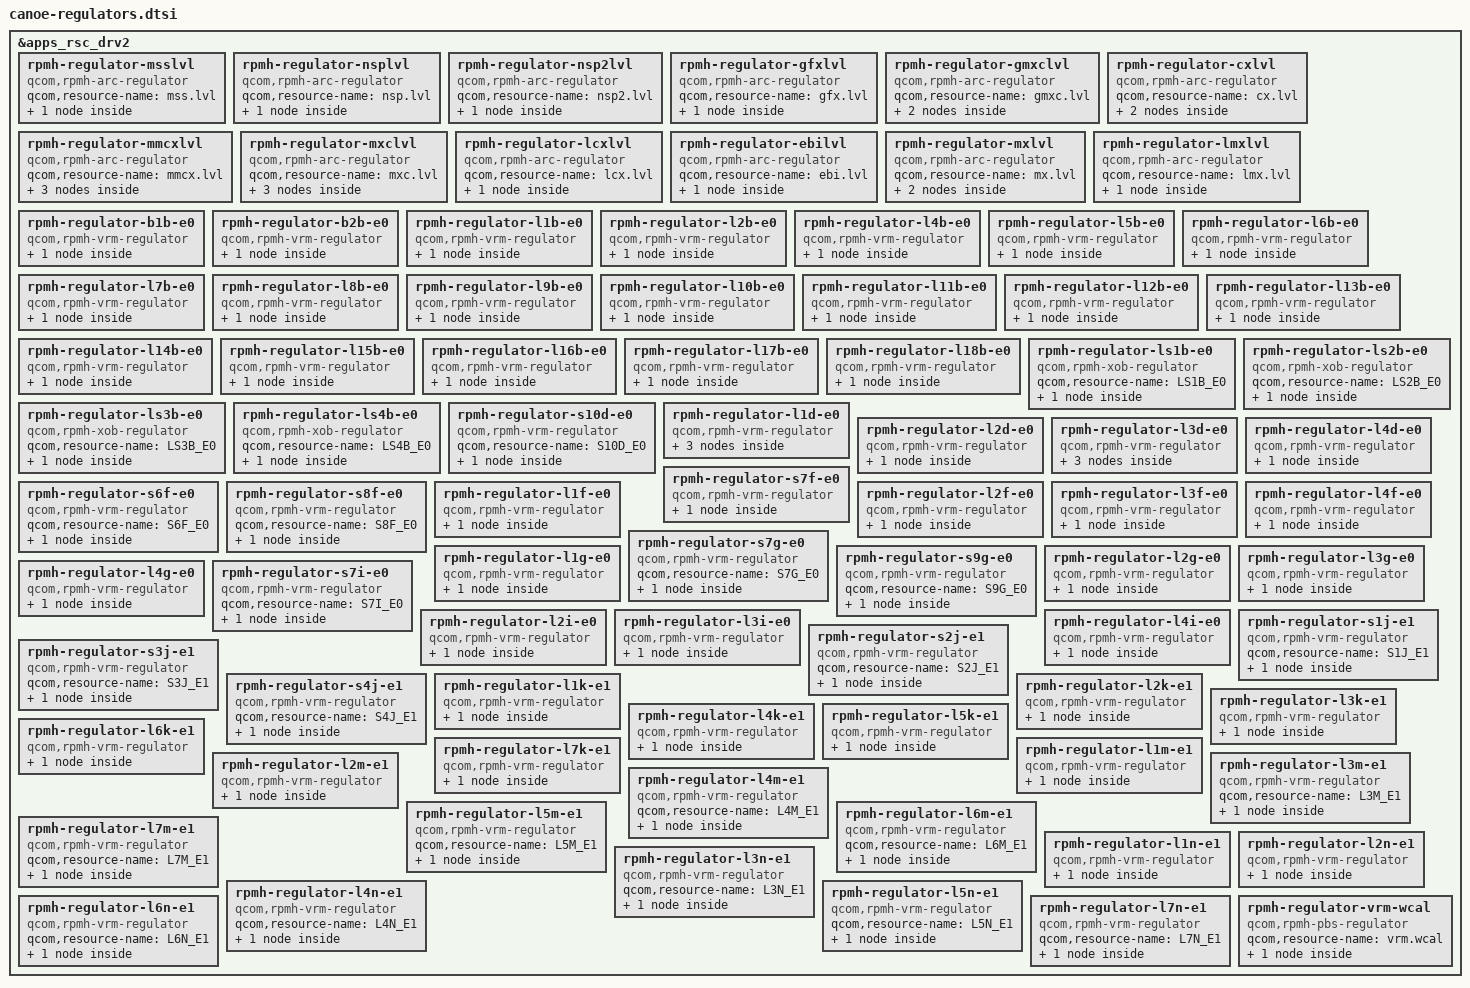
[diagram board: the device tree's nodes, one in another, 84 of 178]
// SPDX-License-Identifier: BSD-3-Clause
/*
 * Copyright (c) Qualcomm Technologies, Inc. and/or its subsidiaries.
 */

#include <dt-bindings/regulator/qcom,rpmh-regulator-levels.h>

&apps_rsc_drv2 {
	rpmh-regulator-msslvl {
		compatible = "qcom,rpmh-arc-regulator";
		qcom,resource-name = "mss.lvl";

		VDD_MODEM_LEVEL: S1D_LEVEL: S1D_E0_LEVEL:
		pmh0110_d_s1_level: regulator-pmh0110-d-s1-level {
			regulator-name = "pmh0110_d_s1_level";
			qcom,set = <RPMH_REGULATOR_SET_ALL>;
			regulator-min-microvolt =
				<RPMH_REGULATOR_LEVEL_RETENTION>;
			regulator-max-microvolt =
				<RPMH_REGULATOR_LEVEL_MAX>;
			qcom,init-voltage-level =
				<RPMH_REGULATOR_LEVEL_RETENTION>;
		};
	};

	rpmh-regulator-nsplvl {
		compatible = "qcom,rpmh-arc-regulator";
		qcom,resource-name = "nsp.lvl";

		/* VDD_NSP1: PMH0110_D S2-S3 */
		VDD_NSP1_LEVEL: S2D_LEVEL: S2D_E0_LEVEL:
		pmh0110_d_s2_level: regulator-pmh0110-d-s2-level {
			regulator-name = "pmh0110_d_s2_level";
			qcom,set = <RPMH_REGULATOR_SET_ALL>;
			regulator-min-microvolt =
				<RPMH_REGULATOR_LEVEL_RETENTION>;
			regulator-max-microvolt =
				<RPMH_REGULATOR_LEVEL_MAX>;
			qcom,init-voltage-level =
				<RPMH_REGULATOR_LEVEL_RETENTION>;
		};
	};

	rpmh-regulator-nsp2lvl {
		compatible = "qcom,rpmh-arc-regulator";
		qcom,resource-name = "nsp2.lvl";

		/* VDD_NSP2: PMH0110_D S4-S6 */
		VDD_NSP2_LEVEL: S4D_LEVEL: S4D_E0_LEVEL:
		pmh0110_d_s4_level: regulator-pmh0110-d-s4-level {
			regulator-name = "pmh0110_d_s4_level";
			qcom,set = <RPMH_REGULATOR_SET_ALL>;
			regulator-min-microvolt =
				<RPMH_REGULATOR_LEVEL_RETENTION>;
			regulator-max-microvolt =
				<RPMH_REGULATOR_LEVEL_MAX>;
			qcom,init-voltage-level =
				<RPMH_REGULATOR_LEVEL_RETENTION>;
		};
	};

	rpmh-regulator-gfxlvl {
		compatible = "qcom,rpmh-arc-regulator";
		qcom,resource-name = "gfx.lvl";

		/* VDD_GFX: PMH0110_F S1-S5 */
		VDD_GFX_LEVEL: S1F_LEVEL: S1F_E0_LEVEL:
		pmh0110_f_s1_level: regulator-pmh0110-f-s1-level {
			regulator-name = "pmh0110_f_s1_level";
			qcom,set = <RPMH_REGULATOR_SET_ALL>;
			regulator-min-microvolt =
				<RPMH_REGULATOR_LEVEL_RETENTION>;
			regulator-max-microvolt =
				<RPMH_REGULATOR_LEVEL_MAX>;
			qcom,init-voltage-level =
				<RPMH_REGULATOR_LEVEL_RETENTION>;
		};
	};

	rpmh-regulator-gmxclvl {
		compatible = "qcom,rpmh-arc-regulator";
		qcom,resource-name = "gmxc.lvl";

		VDD_GFX_MXC_LEVEL: S10F_LEVEL: S10F_E0_LEVEL:
		pmh0110_f_s10_level: regulator-pmh0110-f-s10-level {
			regulator-name = "pmh0110_f_s10_level";
			qcom,set = <RPMH_REGULATOR_SET_ALL>;
			regulator-min-microvolt =
				<RPMH_REGULATOR_LEVEL_RETENTION>;
			regulator-max-microvolt =
				<RPMH_REGULATOR_LEVEL_MAX>;
			qcom,init-voltage-level =
				<RPMH_REGULATOR_LEVEL_RETENTION>;
		};

		VDD_GFX_MXC_GFX_VOTER_LEVEL: VDD_GFX_GFX_MXC_VOTER_LEVEL:
		regulator-pmh0110-f-s10-gfx-voter-level {
			regulator-name = "pmh0110_f_s10_gfx_voter_level";
			qcom,set = <RPMH_REGULATOR_SET_ALL>;
			pmh0110_f_s10_gfx_voter_level-parent-supply =
				<&VDD_GFX_LEVEL>;
			regulator-min-microvolt =
				<RPMH_REGULATOR_LEVEL_MIN_SVS>;
			regulator-max-microvolt =
				<RPMH_REGULATOR_LEVEL_MAX>;
			qcom,init-voltage-level =
				<RPMH_REGULATOR_LEVEL_MIN_SVS>;
		};
	};

	rpmh-regulator-cxlvl {
		compatible = "qcom,rpmh-arc-regulator";
		qcom,resource-name = "cx.lvl";

		/* VDD_CX: PMH0110_G S5-S6 */
		VDD_CX_LEVEL: S5G_LEVEL: S5G_E0_LEVEL:
		pmh0110_g_s5_level: regulator-pmh0110-g-s5-level {
			regulator-name = "pmh0110_g_s5_level";
			qcom,set = <RPMH_REGULATOR_SET_ALL>;
			regulator-min-microvolt =
				<RPMH_REGULATOR_LEVEL_RETENTION>;
			regulator-max-microvolt =
				<RPMH_REGULATOR_LEVEL_MAX>;
			qcom,init-voltage-level =
				<RPMH_REGULATOR_LEVEL_TURBO>;
			proxy-supply = <&VDD_CX_LEVEL>;
			qcom,proxy-consumer-enable;
			qcom,proxy-consumer-voltage =
				<RPMH_REGULATOR_LEVEL_TURBO
				 RPMH_REGULATOR_LEVEL_MAX>;
		};

		VDD_CX_LEVEL_AO: S5G_LEVEL_AO: S5G_E0_LEVEL_AO:
		pmh0110_g_s5_level_ao: regulator-pmh0110-g-s5-level-ao {
			regulator-name = "pmh0110_g_s5_level_ao";
			qcom,set = <RPMH_REGULATOR_SET_ACTIVE>;
			regulator-min-microvolt =
				<RPMH_REGULATOR_LEVEL_RETENTION>;
			regulator-max-microvolt =
				<RPMH_REGULATOR_LEVEL_MAX>;
			qcom,init-voltage-level =
				<RPMH_REGULATOR_LEVEL_RETENTION>;
		};
	};

	rpmh-regulator-mmcxlvl {
		compatible = "qcom,rpmh-arc-regulator";
		qcom,resource-name = "mmcx.lvl";

		/* VDD_MMCX: PMH0110_D S7-S9 */
		VDD_MMCX_LEVEL: VDD_MM_LEVEL: S7D_LEVEL: S7D_E0_LEVEL:
		pmh0110_d_s7_level: regulator-pmh0110-d-s7-level {
			regulator-name = "pmh0110_d_s7_level";
			qcom,set = <RPMH_REGULATOR_SET_ALL>;
			regulator-min-microvolt =
				<RPMH_REGULATOR_LEVEL_LOW_SVS_D1>;
			regulator-max-microvolt =
				<RPMH_REGULATOR_LEVEL_MAX>;
			qcom,init-voltage-level =
				<RPMH_REGULATOR_LEVEL_TURBO>;
			proxy-supply = <&VDD_MMCX_LEVEL>;
			qcom,proxy-consumer-enable;
			qcom,proxy-consumer-voltage =
				<RPMH_REGULATOR_LEVEL_TURBO
				 RPMH_REGULATOR_LEVEL_MAX>;
		};

		VDD_MMCX_LEVEL_AO: VDD_MM_LEVEL_AO: S7D_LEVEL_AO: S7D_E0_LEVEL_AO:
		pmh0110_d_s7_level_ao: regulator-pmh0110-d-s7-level-ao {
			regulator-name = "pmh0110_d_s7_level_ao";
			qcom,set = <RPMH_REGULATOR_SET_ACTIVE>;
			regulator-min-microvolt =
				<RPMH_REGULATOR_LEVEL_LOW_SVS_D1>;
			regulator-max-microvolt =
				<RPMH_REGULATOR_LEVEL_MAX>;
			qcom,init-voltage-level =
				<RPMH_REGULATOR_LEVEL_LOW_SVS_D1>;
		};

		regulator-pmh0110-d-s7-level-so {
			regulator-name = "pmh0110_d_s7_level_so";
			qcom,set = <RPMH_REGULATOR_SET_SLEEP>;
			regulator-min-microvolt =
				<RPMH_REGULATOR_LEVEL_LOW_SVS_D1>;
			regulator-max-microvolt =
				<RPMH_REGULATOR_LEVEL_MAX>;
			qcom,init-voltage-level =
				<RPMH_REGULATOR_LEVEL_LOW_SVS_D1>;
		};
	};

	rpmh-regulator-mxclvl {
		compatible = "qcom,rpmh-arc-regulator";
		qcom,resource-name = "mxc.lvl";

		VDD_MXC_LEVEL: S9F_LEVEL: S9F_E0_LEVEL:
		pmh0110_f_s9_level: regulator-pmh0110-f-s9-level {
			regulator-name = "pmh0110_f_s9_level";
			qcom,set = <RPMH_REGULATOR_SET_ALL>;
			regulator-min-microvolt =
				<RPMH_REGULATOR_LEVEL_RETENTION>;
			regulator-max-microvolt =
				<RPMH_REGULATOR_LEVEL_MAX>;
			qcom,init-voltage-level =
				<RPMH_REGULATOR_LEVEL_TURBO>;
			proxy-supply = <&VDD_MXC_LEVEL>;
			qcom,proxy-consumer-enable;
			qcom,proxy-consumer-voltage =
				<RPMH_REGULATOR_LEVEL_TURBO
				 RPMH_REGULATOR_LEVEL_MAX>;
		};

		VDD_MXC_LEVEL_AO: S9F_LEVEL_AO: S9F_E0_LEVEL_AO:
		pmh0110_f_s9_level_ao: regulator-pmh0110-f-s9-level-ao {
			regulator-name = "pmh0110_f_s9_level_ao";
			qcom,set = <RPMH_REGULATOR_SET_ACTIVE>;
			regulator-min-microvolt =
				<RPMH_REGULATOR_LEVEL_RETENTION>;
			regulator-max-microvolt =
				<RPMH_REGULATOR_LEVEL_MAX>;
			qcom,init-voltage-level =
				<RPMH_REGULATOR_LEVEL_RETENTION>;
		};

		VDD_MXC_MMCX_VOTER_LEVEL: VDD_MXC_MM_VOTER_LEVEL:
		VDD_MM_MXC_VOTER_LEVEL: regulator-pmh0110-f-s9-mmcx-voter-level {
			regulator-name = "pmh0110_f_s9_mmcx_voter_level";
			qcom,set = <RPMH_REGULATOR_SET_ALL>;
			pmh0110_f_s9_mmcx_voter_level-parent-supply =
				<&VDD_MMCX_LEVEL>;
			regulator-min-microvolt =
				<RPMH_REGULATOR_LEVEL_MIN_SVS>;
			regulator-max-microvolt =
				<RPMH_REGULATOR_LEVEL_MAX>;
			qcom,init-voltage-level =
				<RPMH_REGULATOR_LEVEL_MIN_SVS>;
		};
	};

	rpmh-regulator-lcxlvl {
		compatible = "qcom,rpmh-arc-regulator";
		qcom,resource-name = "lcx.lvl";

		VDD_LPI_CX_LEVEL: S8G_LEVEL: S8G_E0_LEVEL:
		pmh0110_g_s8_level: regulator-pmh0110-g-s8-level {
			regulator-name = "pmh0110_g_s8_level";
			qcom,set = <RPMH_REGULATOR_SET_ALL>;
			regulator-min-microvolt =
				<RPMH_REGULATOR_LEVEL_RETENTION>;
			regulator-max-microvolt =
				<RPMH_REGULATOR_LEVEL_MAX>;
			qcom,init-voltage-level =
				<RPMH_REGULATOR_LEVEL_RETENTION>;
		};
	};

	rpmh-regulator-ebilvl {
		compatible = "qcom,rpmh-arc-regulator";
		qcom,resource-name = "ebi.lvl";

		VDD_EBI_LEVEL: S1I_LEVEL: S1I_E0_LEVEL:
		pmh0110_i_s1_level: regulator-pmh0110-i-s1-level {
			regulator-name = "pmh0110_i_s1_level";
			qcom,set = <RPMH_REGULATOR_SET_ALL>;
			regulator-min-microvolt =
				<RPMH_REGULATOR_LEVEL_RETENTION>;
			regulator-max-microvolt =
				<RPMH_REGULATOR_LEVEL_MAX>;
			qcom,init-voltage-level =
				<RPMH_REGULATOR_LEVEL_RETENTION>;
		};
	};

	rpmh-regulator-mxlvl {
		compatible = "qcom,rpmh-arc-regulator";
		qcom,resource-name = "mx.lvl";

		VDD_MXA_LEVEL: VDD_MX_LEVEL: S10I_LEVEL: S10I_E0_LEVEL:
		pmh0110_i_s10_level: regulator-pmh0110-i-s10-level {
			regulator-name = "pmh0110_i_s10_level";
			qcom,set = <RPMH_REGULATOR_SET_ALL>;
			regulator-min-microvolt =
				<RPMH_REGULATOR_LEVEL_RETENTION>;
			regulator-max-microvolt =
				<RPMH_REGULATOR_LEVEL_MAX>;
			qcom,init-voltage-level =
				<RPMH_REGULATOR_LEVEL_TURBO>;
			proxy-supply = <&VDD_MXA_LEVEL>;
			qcom,proxy-consumer-enable;
			qcom,proxy-consumer-voltage =
				<RPMH_REGULATOR_LEVEL_TURBO
				 RPMH_REGULATOR_LEVEL_MAX>;
		};

		VDD_MXA_LEVEL_AO: VDD_MX_LEVEL_AO: S10I_LEVEL_AO: S10I_E0_LEVEL_AO:
		pmh0110_i_s10_level_ao: regulator-pmh0110-i-s10-level-ao {
			regulator-name = "pmh0110_i_s10_level_ao";
			qcom,set = <RPMH_REGULATOR_SET_ACTIVE>;
			regulator-min-microvolt =
				<RPMH_REGULATOR_LEVEL_RETENTION>;
			regulator-max-microvolt =
				<RPMH_REGULATOR_LEVEL_MAX>;
			qcom,init-voltage-level =
				<RPMH_REGULATOR_LEVEL_RETENTION>;
		};
	};

	rpmh-regulator-lmxlvl {
		compatible = "qcom,rpmh-arc-regulator";
		qcom,resource-name = "lmx.lvl";

		VDD_LPI_MX_LEVEL: L1I_LEVEL: L1I_E0_LEVEL:
		pmh0110_i_l1_level: regulator-pmh0110-i-l1-level {
			regulator-name = "pmh0110_i_l1_level";
			qcom,set = <RPMH_REGULATOR_SET_ALL>;
			regulator-min-microvolt =
				<RPMH_REGULATOR_LEVEL_RETENTION>;
			regulator-max-microvolt =
				<RPMH_REGULATOR_LEVEL_MAX>;
			qcom,init-voltage-level =
				<RPMH_REGULATOR_LEVEL_RETENTION>;
		};
	};

	rpmh-regulator-b1b-e0 {
		compatible = "qcom,rpmh-vrm-regulator";
		qcom,resource-name = "B1B_E0";
		qcom,regulator-type = "pmic5-bob";
		qcom,supported-modes =
			<RPMH_REGULATOR_MODE_PASS
			RPMH_REGULATOR_MODE_AUTO
			RPMH_REGULATOR_MODE_HPM>;
		qcom,mode-threshold-currents = <0 1000000 2000000>;

		BOB1: BOB1_E0: pmh0101_bob1: regulator-pmh0101-bob1 {
			regulator-name = "pmh0101_bob1";
			qcom,set = <RPMH_REGULATOR_SET_ALL>;
			regulator-min-microvolt = <3008000>;
			regulator-max-microvolt = <4000000>;
			qcom,init-voltage = <3296000>;
			qcom,init-mode = <RPMH_REGULATOR_MODE_PASS>;
		};
	};

	rpmh-regulator-b2b-e0 {
		compatible = "qcom,rpmh-vrm-regulator";
		qcom,resource-name = "B2B_E0";
		qcom,regulator-type = "pmic5-bob";
		qcom,supported-modes =
			<RPMH_REGULATOR_MODE_PASS
			RPMH_REGULATOR_MODE_AUTO
			RPMH_REGULATOR_MODE_HPM>;
		qcom,mode-threshold-currents = <0 1000000 2000000>;

		BOB2: BOB2_E0: pmh0101_bob2: regulator-pmh0101-bob2 {
			regulator-name = "pmh0101_bob2";
			qcom,set = <RPMH_REGULATOR_SET_ALL>;
			regulator-min-microvolt = <2704000>;
			regulator-max-microvolt = <3552000>;
			qcom,init-voltage = <2720000>;
			qcom,init-mode = <RPMH_REGULATOR_MODE_PASS>;
		};
	};

	rpmh-regulator-l1b-e0 {
		compatible = "qcom,rpmh-vrm-regulator";
		qcom,resource-name = "L1B_E0";
		qcom,regulator-type = "pmic7-ldo";
		qcom,supported-modes = <RPMH_REGULATOR_MODE_LPM
					RPMH_REGULATOR_MODE_AUTO>;
		qcom,mode-threshold-currents = <0 30000>;

		L1B: L1B_E0: pmh0101_l1: regulator-pmh0101-l1 {
			regulator-name = "pmh0101_l1";
			qcom,set = <RPMH_REGULATOR_SET_ALL>;
			regulator-min-microvolt = <1800000>;
			regulator-max-microvolt = <1800000>;
			qcom,init-voltage = <1800000>;
			qcom,init-mode = <RPMH_REGULATOR_MODE_AUTO>;
		};
	};

	rpmh-regulator-l2b-e0 {
		compatible = "qcom,rpmh-vrm-regulator";
		qcom,resource-name = "L2B_E0";
		qcom,regulator-type = "pmic7-ldo";
		qcom,supported-modes = <RPMH_REGULATOR_MODE_LPM
					RPMH_REGULATOR_MODE_AUTO>;
		qcom,mode-threshold-currents = <0 20000>;

		L2B: L2B_E0: pmh0101_l2: regulator-pmh0101-l2 {
			regulator-name = "pmh0101_l2";
			qcom,set = <RPMH_REGULATOR_SET_ALL>;
			regulator-min-microvolt = <3008000>;
			regulator-max-microvolt = <3048000>;
			qcom,init-voltage = <3008000>;
			qcom,init-mode = <RPMH_REGULATOR_MODE_AUTO>;
		};
	};

	rpmh-regulator-l4b-e0 {
		compatible = "qcom,rpmh-vrm-regulator";
		qcom,resource-name = "L4B_E0";
		qcom,regulator-type = "pmic7-ldo";
		qcom,supported-modes = <RPMH_REGULATOR_MODE_LPM
					RPMH_REGULATOR_MODE_AUTO>;
		qcom,mode-threshold-currents = <0 30000>;

		L4B: L4B_E0: pmh0101_l4: regulator-pmh0101-l4 {
			regulator-name = "pmh0101_l4";
			qcom,set = <RPMH_REGULATOR_SET_ALL>;
			regulator-min-microvolt = <1800000>;
			regulator-max-microvolt = <1800000>;
			qcom,init-voltage = <1800000>;
			qcom,init-mode = <RPMH_REGULATOR_MODE_AUTO>;
		};
	};

	rpmh-regulator-l5b-e0 {
		compatible = "qcom,rpmh-vrm-regulator";
		qcom,resource-name = "L5B_E0";
		qcom,regulator-type = "pmic7-ldo";
		qcom,supported-modes = <RPMH_REGULATOR_MODE_LPM
					RPMH_REGULATOR_MODE_AUTO>;
		qcom,mode-threshold-currents = <0 10000>;

		L5B: L5B_E0: pmh0101_l5: regulator-pmh0101-l5 {
			regulator-name = "pmh0101_l5";
			qcom,set = <RPMH_REGULATOR_SET_ALL>;
			regulator-min-microvolt = <3100000>;
			regulator-max-microvolt = <3148000>;
			qcom,init-voltage = <3104000>;
			qcom,init-mode = <RPMH_REGULATOR_MODE_AUTO>;
		};
	};

	rpmh-regulator-l6b-e0 {
		compatible = "qcom,rpmh-vrm-regulator";
		qcom,resource-name = "L6B_E0";
		qcom,regulator-type = "pmic7-ldo";
		qcom,supported-modes = <RPMH_REGULATOR_MODE_LPM
					RPMH_REGULATOR_MODE_AUTO>;
		qcom,mode-threshold-currents = <0 20000>;

		L6B: L6B_E0: pmh0101_l6: regulator-pmh0101-l6 {
			regulator-name = "pmh0101_l6";
			qcom,set = <RPMH_REGULATOR_SET_ALL>;
			regulator-min-microvolt = <1800000>;
			regulator-max-microvolt = <3008000>;
			qcom,init-voltage = <1800000>;
			qcom,init-mode = <RPMH_REGULATOR_MODE_AUTO>;
		};
	};

	rpmh-regulator-l7b-e0 {
		compatible = "qcom,rpmh-vrm-regulator";
		qcom,resource-name = "L7B_E0";
		qcom,regulator-type = "pmic7-ldo";
		qcom,supported-modes = <RPMH_REGULATOR_MODE_LPM
					RPMH_REGULATOR_MODE_AUTO>;
		qcom,mode-threshold-currents = <0 20000>;

		L7B: L7B_E0: pmh0101_l7: regulator-pmh0101-l7 {
			regulator-name = "pmh0101_l7";
			qcom,set = <RPMH_REGULATOR_SET_ALL>;
			regulator-min-microvolt = <1800000>;
			regulator-max-microvolt = <3008000>;
			qcom,init-voltage = <1800000>;
			qcom,init-mode = <RPMH_REGULATOR_MODE_AUTO>;
		};
	};

	rpmh-regulator-l8b-e0 {
		compatible = "qcom,rpmh-vrm-regulator";
		qcom,resource-name = "L8B_E0";
		qcom,regulator-type = "pmic7-ldo";
		qcom,supported-modes = <RPMH_REGULATOR_MODE_LPM
					RPMH_REGULATOR_MODE_AUTO>;
		qcom,mode-threshold-currents = <0 10000>;

		L8B: L8B_E0: pmh0101_l8: regulator-pmh0101-l8 {
			regulator-name = "pmh0101_l8";
			qcom,set = <RPMH_REGULATOR_SET_ALL>;
			regulator-min-microvolt = <1800000>;
			regulator-max-microvolt = <3008000>;
			qcom,init-voltage = <1800000>;
			qcom,init-mode = <RPMH_REGULATOR_MODE_AUTO>;
		};
	};

	rpmh-regulator-l9b-e0 {
		compatible = "qcom,rpmh-vrm-regulator";
		qcom,resource-name = "L9B_E0";
		qcom,regulator-type = "pmic5-ldo";
		qcom,supported-modes = <RPMH_REGULATOR_MODE_LPM
					RPMH_REGULATOR_MODE_HPM>;
		qcom,mode-threshold-currents = <0 80000>;

		L9B: L9B_E0: pmh0101_l9: regulator-pmh0101-l9 {
			regulator-name = "pmh0101_l9";
			qcom,set = <RPMH_REGULATOR_SET_ALL>;
			regulator-min-microvolt = <2960000>;
			regulator-max-microvolt = <3300000>;
			qcom,init-voltage = <2960000>;
			qcom,init-mode = <RPMH_REGULATOR_MODE_HPM>;
		};
	};

	rpmh-regulator-l10b-e0 {
		compatible = "qcom,rpmh-vrm-regulator";
		qcom,resource-name = "L10B_E0";
		qcom,regulator-type = "pmic7-ldo";
		qcom,supported-modes = <RPMH_REGULATOR_MODE_LPM
					RPMH_REGULATOR_MODE_AUTO>;
		qcom,mode-threshold-currents = <0 30000>;
		proxy-supply = <&L10B>;

		L10B: L10B_E0: pmh0101_l10: regulator-pmh0101-l10 {
			regulator-name = "pmh0101_l10";
			qcom,set = <RPMH_REGULATOR_SET_ALL>;
			regulator-min-microvolt = <1800000>;
			regulator-max-microvolt = <1800000>;
			qcom,init-voltage = <1800000>;
			qcom,init-mode = <RPMH_REGULATOR_MODE_AUTO>;
			qcom,proxy-consumer-enable;
		};
	};

	rpmh-regulator-l11b-e0 {
		compatible = "qcom,rpmh-vrm-regulator";
		qcom,resource-name = "L11B_E0";
		qcom,regulator-type = "pmic7-ldo";
		qcom,supported-modes = <RPMH_REGULATOR_MODE_LPM
					RPMH_REGULATOR_MODE_AUTO>;
		qcom,mode-threshold-currents = <0 30000>;
		proxy-supply = <&L11B>;

		L11B: L11B_E0: pmh0101_l11: regulator-pmh0101-l11 {
			regulator-name = "pmh0101_l11";
			qcom,set = <RPMH_REGULATOR_SET_ALL>;
			regulator-min-microvolt = <1000000>;
			regulator-max-microvolt = <1292000>;
			qcom,init-voltage = <1064000>;
			qcom,init-mode = <RPMH_REGULATOR_MODE_AUTO>;
			qcom,proxy-consumer-enable;
		};
	};

	rpmh-regulator-l12b-e0 {
		compatible = "qcom,rpmh-vrm-regulator";
		qcom,resource-name = "L12B_E0";
		qcom,regulator-type = "pmic7-ldo";
		qcom,supported-modes = <RPMH_REGULATOR_MODE_LPM
					RPMH_REGULATOR_MODE_AUTO>;
		qcom,mode-threshold-currents = <0 30000>;
		proxy-supply = <&L12B>;

		L12B: L12B_E0: pmh0101_l12: regulator-pmh0101-l12 {
			regulator-name = "pmh0101_l12";
			qcom,set = <RPMH_REGULATOR_SET_ALL>;
			regulator-min-microvolt = <1200000>;
			regulator-max-microvolt = <1800000>;
			qcom,init-voltage = <1800000>;
			qcom,init-mode = <RPMH_REGULATOR_MODE_AUTO>;
			qcom,proxy-consumer-enable;
		};
	};

	rpmh-regulator-l13b-e0 {
		compatible = "qcom,rpmh-vrm-regulator";
		qcom,resource-name = "L13B_E0";
		qcom,regulator-type = "pmic7-ldo";
		qcom,supported-modes = <RPMH_REGULATOR_MODE_LPM
					RPMH_REGULATOR_MODE_AUTO>;
		qcom,mode-threshold-currents = <0 10000>;
		proxy-supply = <&L13B>;

		L13B: L13B_E0: pmh0101_l13: regulator-pmh0101-l13 {
			regulator-name = "pmh0101_l13";
			qcom,set = <RPMH_REGULATOR_SET_ALL>;
			regulator-min-microvolt = <3000000>;
			regulator-max-microvolt = <3000000>;
			qcom,init-voltage = <3000000>;
			qcom,init-mode = <RPMH_REGULATOR_MODE_AUTO>;
			qcom,proxy-consumer-enable;
		};
	};

	rpmh-regulator-l14b-e0 {
		compatible = "qcom,rpmh-vrm-regulator";
		qcom,resource-name = "L14B_E0";
		qcom,regulator-type = "pmic7-ldo";
		qcom,supported-modes = <RPMH_REGULATOR_MODE_LPM
					RPMH_REGULATOR_MODE_AUTO>;
		qcom,mode-threshold-currents = <0 10000>;

		L14B: L14B_E0: pmh0101_l14: regulator-pmh0101-l14 {
			regulator-name = "pmh0101_l14";
			qcom,set = <RPMH_REGULATOR_SET_ALL>;
			regulator-min-microvolt = <3200000>;
			regulator-max-microvolt = <3200000>;
			qcom,init-voltage = <3200000>;
			qcom,init-mode = <RPMH_REGULATOR_MODE_AUTO>;
		};
	};

	rpmh-regulator-l15b-e0 {
		compatible = "qcom,rpmh-vrm-regulator";
		qcom,resource-name = "L15B_E0";
		qcom,regulator-type = "pmic7-ldo";
		qcom,supported-modes = <RPMH_REGULATOR_MODE_LPM
					RPMH_REGULATOR_MODE_AUTO>;
		qcom,mode-threshold-currents = <0 30000>;

		L15B: L15B_E0: pmh0101_l15: regulator-pmh0101-l15 {
			regulator-name = "pmh0101_l15";
			qcom,set = <RPMH_REGULATOR_SET_ALL>;
			regulator-min-microvolt = <1800000>;
			regulator-max-microvolt = <1800000>;
			qcom,init-voltage = <1800000>;
			qcom,init-mode = <RPMH_REGULATOR_MODE_AUTO>;
		};
	};

	rpmh-regulator-l16b-e0 {
		compatible = "qcom,rpmh-vrm-regulator";
		qcom,resource-name = "L16B_E0";
		qcom,regulator-type = "pmic7-ldo";
		qcom,supported-modes = <RPMH_REGULATOR_MODE_LPM
					RPMH_REGULATOR_MODE_HPM>;
		qcom,mode-threshold-currents = <0 10000>;

		L16B: L16B_E0: pmh0101_l16: regulator-pmh0101-l16 {
			regulator-name = "pmh0101_l16";
			qcom,set = <RPMH_REGULATOR_SET_ALL>;
			regulator-min-microvolt = <1504000>;
			regulator-max-microvolt = <3300000>;
			qcom,init-voltage = <3300000>;
			qcom,init-mode = <RPMH_REGULATOR_MODE_HPM>;
		};
	};

	rpmh-regulator-l17b-e0 {
		compatible = "qcom,rpmh-vrm-regulator";
		qcom,resource-name = "L17B_E0";
		qcom,regulator-type = "pmic5-ldo";
		qcom,supported-modes = <RPMH_REGULATOR_MODE_LPM
					RPMH_REGULATOR_MODE_HPM>;
		qcom,mode-threshold-currents = <0 80000>;

		L17B: L17B_E0: pmh0101_l17: regulator-pmh0101-l17 {
			regulator-name = "pmh0101_l17";
			qcom,set = <RPMH_REGULATOR_SET_ALL>;
			regulator-min-microvolt = <2504000>;
			regulator-max-microvolt = <2504000>;
			qcom,init-voltage = <2504000>;
			qcom,init-mode = <RPMH_REGULATOR_MODE_HPM>;
		};
	};

	rpmh-regulator-l18b-e0 {
		compatible = "qcom,rpmh-vrm-regulator";
		qcom,resource-name = "L18B_E0";
		qcom,regulator-type = "pmic7-ldo";
		qcom,supported-modes = <RPMH_REGULATOR_MODE_LPM
					RPMH_REGULATOR_MODE_AUTO>;
		qcom,mode-threshold-currents = <0 30000>;

		L18B: L18B_E0: pmh0101_l18: regulator-pmh0101-l18 {
			regulator-name = "pmh0101_l18";
			qcom,set = <RPMH_REGULATOR_SET_ALL>;
			regulator-min-microvolt = <1200000>;
			regulator-max-microvolt = <1200000>;
			qcom,init-voltage = <1200000>;
			qcom,init-mode = <RPMH_REGULATOR_MODE_AUTO>;
		};
	};

	rpmh-regulator-ls1b-e0 {
		compatible = "qcom,rpmh-xob-regulator";
		qcom,resource-name = "LS1B_E0";

		/* PMH0101 GPIO 11 and 12 bi-directional level-shifter */
		LS1B: LS1B_E0: pmh0101_ls1: regulator-pmh0101-ls1 {
			regulator-name = "pmh0101_ls1";
			qcom,set = <RPMH_REGULATOR_SET_ALL>;
		};
	};

	rpmh-regulator-ls2b-e0 {
		compatible = "qcom,rpmh-xob-regulator";
		qcom,resource-name = "LS2B_E0";

		/* PMH0101 GPIO 13 and 14 bi-directional level-shifter */
		LS2B: LS2B_E0: pmh0101_ls2: regulator-pmh0101-ls2 {
			regulator-name = "pmh0101_ls2";
			qcom,set = <RPMH_REGULATOR_SET_ALL>;
		};
	};

	rpmh-regulator-ls3b-e0 {
		compatible = "qcom,rpmh-xob-regulator";
		qcom,resource-name = "LS3B_E0";

		/* PMH0101 GPIO 15 and 16 bi-directional level-shifter */
		LS3B: LS3B_E0: pmh0101_ls3: regulator-pmh0101-ls3 {
			regulator-name = "pmh0101_ls3";
			qcom,set = <RPMH_REGULATOR_SET_ALL>;
		};
	};

	rpmh-regulator-ls4b-e0 {
		compatible = "qcom,rpmh-xob-regulator";
		qcom,resource-name = "LS4B_E0";

		/* PMH0101 GPIO 17 and 18 bi-directional level-shifter */
		LS4B: LS4B_E0: pmh0101_ls4: regulator-pmh0101-ls4 {
			regulator-name = "pmh0101_ls4";
			qcom,set = <RPMH_REGULATOR_SET_ALL>;
		};
	};

	rpmh-regulator-s10d-e0 {
		compatible = "qcom,rpmh-vrm-regulator";
		qcom,resource-name = "S10D_E0";

		S10D: S10D_E0: pmh0110_d_s10: regulator-pmh0110-d-s10 {
			regulator-name = "pmh0110_d_s10";
			qcom,set = <RPMH_REGULATOR_SET_ALL>;
			regulator-min-microvolt = <1000000>;
			regulator-max-microvolt = <1100000>;
			qcom,init-voltage = <1052000>;
		};
	};

	rpmh-regulator-l1d-e0 {
		compatible = "qcom,rpmh-vrm-regulator";
		qcom,resource-name = "L1D_E0";
		qcom,regulator-type = "pmic7-ldo";
		qcom,supported-modes = <RPMH_REGULATOR_MODE_LPM
					RPMH_REGULATOR_MODE_AUTO>;
		qcom,mode-threshold-currents = <0 30000>;
		qcom,send-defaults;
		proxy-supply = <&L1D>;

		L1D: L1D_E0: pmh0110_d_l1: regulator-pmh0110-d-l1 {
			regulator-name = "pmh0110_d_l1";
			qcom,set = <RPMH_REGULATOR_SET_ALL>;
			regulator-min-microvolt = <1200000>;
			regulator-max-microvolt = <1256000>;
			qcom,init-voltage = <1200000>;
			qcom,init-mode = <RPMH_REGULATOR_MODE_AUTO>;
			qcom,proxy-consumer-enable;
		};

		L1D_AO: L1D_E0_AO: pmh0110_d_l1_ao: regulator-pmh0110-d-l1-ao {
			regulator-name = "pmh0110_d_l1_ao";
			qcom,set = <RPMH_REGULATOR_SET_ACTIVE>;
			regulator-min-microvolt = <1200000>;
			regulator-max-microvolt = <1256000>;
			qcom,init-voltage = <1200000>;
			qcom,init-mode = <RPMH_REGULATOR_MODE_AUTO>;
			regulator-always-on;
		};

		regulator-pmh0110-d-l1-so {
			regulator-name = "pmh0110_d_l1_so";
			qcom,set = <RPMH_REGULATOR_SET_SLEEP>;
			regulator-min-microvolt = <1200000>;
			regulator-max-microvolt = <1256000>;
			qcom,init-voltage = <1200000>;
			qcom,init-mode = <RPMH_REGULATOR_MODE_LPM>;
			qcom,init-enable = <0>;
		};
	};

	rpmh-regulator-l2d-e0 {
		compatible = "qcom,rpmh-vrm-regulator";
		qcom,resource-name = "L2D_E0";
		qcom,regulator-type = "pmic7-ldo";
		qcom,supported-modes = <RPMH_REGULATOR_MODE_LPM
					RPMH_REGULATOR_MODE_AUTO>;
		qcom,mode-threshold-currents = <0 30000>;

		L2D: L2D_E0: pmh0110_d_l2: regulator-pmh0110-d-l2 {
			regulator-name = "pmh0110_d_l2";
			qcom,set = <RPMH_REGULATOR_SET_ALL>;
			regulator-min-microvolt = <912000>;
			regulator-max-microvolt = <958000>;
			qcom,init-voltage = <912000>;
			qcom,init-mode = <RPMH_REGULATOR_MODE_AUTO>;
		};
	};

	rpmh-regulator-l3d-e0 {
		compatible = "qcom,rpmh-vrm-regulator";
		qcom,resource-name = "L3D_E0";
		qcom,regulator-type = "pmic7-ldo";
		qcom,supported-modes = <RPMH_REGULATOR_MODE_LPM
					RPMH_REGULATOR_MODE_AUTO>;
		qcom,mode-threshold-currents = <0 30000>;
		qcom,send-defaults;
		proxy-supply = <&L3D>;

		L3D: L3D_E0: pmh0110_d_l3: regulator-pmh0110-d-l3 {
			regulator-name = "pmh0110_d_l3";
			qcom,set = <RPMH_REGULATOR_SET_ALL>;
			regulator-min-microvolt = <880000>;
			regulator-max-microvolt = <880000>;
			qcom,init-voltage = <880000>;
			qcom,init-mode = <RPMH_REGULATOR_MODE_AUTO>;
			qcom,proxy-consumer-enable;
		};

		L3D_AO: L3D_E0_AO: pmh0110_d_l3_ao: regulator-pmh0110-d-l3-ao {
			regulator-name = "pmh0110_d_l3_ao";
			qcom,set = <RPMH_REGULATOR_SET_ACTIVE>;
			regulator-min-microvolt = <880000>;
			regulator-max-microvolt = <880000>;
			qcom,init-voltage = <880000>;
			qcom,init-mode = <RPMH_REGULATOR_MODE_AUTO>;
			regulator-always-on;
		};

		regulator-pmh0110-d-l3-so {
			regulator-name = "pmh0110_d_l3_so";
			qcom,set = <RPMH_REGULATOR_SET_SLEEP>;
			regulator-min-microvolt = <880000>;
			regulator-max-microvolt = <880000>;
			qcom,init-voltage = <880000>;
			qcom,init-mode = <RPMH_REGULATOR_MODE_LPM>;
			qcom,init-enable = <0>;
		};
	};

	rpmh-regulator-l4d-e0 {
		compatible = "qcom,rpmh-vrm-regulator";
		qcom,resource-name = "L4D_E0";
		qcom,regulator-type = "pmic7-ldo";
		qcom,supported-modes = <RPMH_REGULATOR_MODE_LPM
					RPMH_REGULATOR_MODE_AUTO>;
		qcom,mode-threshold-currents = <0 30000>;

		L4D: L4D_E0: pmh0110_d_l4: regulator-pmh0110-d-l4 {
			regulator-name = "pmh0110_d_l4";
			qcom,set = <RPMH_REGULATOR_SET_ALL>;
			regulator-min-microvolt = <1200000>;
			regulator-max-microvolt = <1200000>;
			qcom,init-voltage = <1200000>;
			qcom,init-mode = <RPMH_REGULATOR_MODE_AUTO>;
		};
	};

	rpmh-regulator-s6f-e0 {
		compatible = "qcom,rpmh-vrm-regulator";
		qcom,resource-name = "S6F_E0";

		S6F: S6F_E0: pmh0110_f_s6: regulator-pmh0110-f-s6 {
			regulator-name = "pmh0110_f_s6";
			qcom,set = <RPMH_REGULATOR_SET_ALL>;
			regulator-min-microvolt = <300000>;
			regulator-max-microvolt = <570000>;
			qcom,init-voltage = <500000>;
		};
	};

	rpmh-regulator-s7f-e0 {
		compatible = "qcom,rpmh-vrm-regulator";
		qcom,resource-name = "S7F_E0";
		qcom,regulator-type = "pmic7-ftsmps";
		qcom,supported-modes =
			<RPMH_REGULATOR_MODE_HPM>;
		qcom,mode-threshold-currents = <0>;

		S7F: S7F_E0: pmh0110_f_s7: regulator-pmh0110-f-s7 {
			regulator-name = "pmh0110_f_s7";
			qcom,set = <RPMH_REGULATOR_SET_ALL>;
			regulator-min-microvolt = <1224000>;
			regulator-max-microvolt = <1372000>;
			qcom,init-voltage = <1256000>;
			qcom,init-mode = <RPMH_REGULATOR_MODE_RET>;
		};
	};

	rpmh-regulator-s8f-e0 {
		compatible = "qcom,rpmh-vrm-regulator";
		qcom,resource-name = "S8F_E0";

		S8F: S8F_E0: pmh0110_f_s8: regulator-pmh0110-f-s8 {
			regulator-name = "pmh0110_f_s8";
			qcom,set = <RPMH_REGULATOR_SET_ALL>;
			regulator-min-microvolt = <1800000>;
			regulator-max-microvolt = <2000000>;
			qcom,init-voltage = <1856000>;
		};
	};

	rpmh-regulator-l1f-e0 {
		compatible = "qcom,rpmh-vrm-regulator";
		qcom,resource-name = "L1F_E0";
		qcom,regulator-type = "pmic7-ldo";
		qcom,supported-modes = <RPMH_REGULATOR_MODE_LPM
					RPMH_REGULATOR_MODE_AUTO>;
		qcom,mode-threshold-currents = <0 30000>;

		L1F: L1F_E0: pmh0110_f_l1: regulator-pmh0110-f-l1 {
			regulator-name = "pmh0110_f_l1";
			qcom,set = <RPMH_REGULATOR_SET_ALL>;
			regulator-min-microvolt = <1200000>;
			regulator-max-microvolt = <1200000>;
			qcom,init-voltage = <1200000>;
			qcom,init-mode = <RPMH_REGULATOR_MODE_AUTO>;
		};
	};

	rpmh-regulator-l2f-e0 {
		compatible = "qcom,rpmh-vrm-regulator";
		qcom,resource-name = "L2F_E0";
		qcom,regulator-type = "pmic7-ldo";
		qcom,supported-modes = <RPMH_REGULATOR_MODE_LPM
					RPMH_REGULATOR_MODE_AUTO>;
		qcom,mode-threshold-currents = <0 30000>;

		L2F: L2F_E0: pmh0110_f_l2: regulator-pmh0110-f-l2 {
			regulator-name = "pmh0110_f_l2";
			qcom,set = <RPMH_REGULATOR_SET_ALL>;
			regulator-min-microvolt = <1200000>;
			regulator-max-microvolt = <1200000>;
			qcom,init-voltage = <1200000>;
			qcom,init-mode = <RPMH_REGULATOR_MODE_AUTO>;
		};
	};

	rpmh-regulator-l3f-e0 {
		compatible = "qcom,rpmh-vrm-regulator";
		qcom,resource-name = "L3F_E0";
		qcom,regulator-type = "pmic7-ldo";
		qcom,supported-modes = <RPMH_REGULATOR_MODE_LPM
					RPMH_REGULATOR_MODE_AUTO>;
		qcom,mode-threshold-currents = <0 30000>;

		L3F: L3F_E0: pmh0110_f_l3: regulator-pmh0110-f-l3 {
			regulator-name = "pmh0110_f_l3";
			qcom,set = <RPMH_REGULATOR_SET_ALL>;
			regulator-min-microvolt = <880000>;
			regulator-max-microvolt = <936000>;
			qcom,init-voltage = <880000>;
			qcom,init-mode = <RPMH_REGULATOR_MODE_AUTO>;
		};
	};

	rpmh-regulator-l4f-e0 {
		compatible = "qcom,rpmh-vrm-regulator";
		qcom,resource-name = "L4F_E0";
		qcom,regulator-type = "pmic7-ldo";
		qcom,supported-modes = <RPMH_REGULATOR_MODE_LPM
					RPMH_REGULATOR_MODE_AUTO>;
		qcom,mode-threshold-currents = <0 30000>;

		L4F: L4F_E0: pmh0110_f_l4: regulator-pmh0110-f-l4 {
			regulator-name = "pmh0110_f_l4";
			qcom,set = <RPMH_REGULATOR_SET_ALL>;
			regulator-min-microvolt = <880000>;
			regulator-max-microvolt = <912000>;
			qcom,init-voltage = <880000>;
			qcom,init-mode = <RPMH_REGULATOR_MODE_AUTO>;
		};
	};

	rpmh-regulator-s7g-e0 {
		compatible = "qcom,rpmh-vrm-regulator";
		qcom,resource-name = "S7G_E0";

		S7G: S7G_E0: pmh0110_g_s7: regulator-pmh0110-g-s7 {
			regulator-name = "pmh0110_g_s7";
			qcom,set = <RPMH_REGULATOR_SET_ALL>;
			regulator-min-microvolt = <880000>;
			regulator-max-microvolt = <1100000>;
			qcom,init-voltage = <976000>;
		};
	};

	rpmh-regulator-s9g-e0 {
		compatible = "qcom,rpmh-vrm-regulator";
		qcom,resource-name = "S9G_E0";

		S9G: S9G_E0: pmh0110_g_s9: regulator-pmh0110-g-s9 {
			regulator-name = "pmh0110_g_s9";
			qcom,set = <RPMH_REGULATOR_SET_ALL>;
			regulator-min-microvolt = <1000000>;
			regulator-max-microvolt = <1100000>;
			qcom,init-voltage = <1052000>;
		};
	};

	rpmh-regulator-l1g-e0 {
		compatible = "qcom,rpmh-vrm-regulator";
		qcom,resource-name = "L1G_E0";
		qcom,regulator-type = "pmic7-ldo";
		qcom,supported-modes = <RPMH_REGULATOR_MODE_RET
					RPMH_REGULATOR_MODE_AUTO>;
		qcom,mode-threshold-currents = <0 30000>;

		L1G: L1G_E0: pmh0110_g_l1: regulator-pmh0110-g-l1 {
			regulator-name = "pmh0110_g_l1";
			qcom,set = <RPMH_REGULATOR_SET_ALL>;
			regulator-min-microvolt = <1200000>;
			regulator-max-microvolt = <1200000>;
			qcom,init-voltage = <1200000>;
			qcom,init-mode = <RPMH_REGULATOR_MODE_AUTO>;
		};
	};

	rpmh-regulator-l2g-e0 {
		compatible = "qcom,rpmh-vrm-regulator";
		qcom,resource-name = "L2G_E0";
		qcom,regulator-type = "pmic7-ldo";
		qcom,supported-modes = <RPMH_REGULATOR_MODE_LPM
					RPMH_REGULATOR_MODE_AUTO>;
		qcom,mode-threshold-currents = <0 30000>;

		L2G: L2G_E0: pmh0110_g_l2: regulator-pmh0110-g-l2 {
			regulator-name = "pmh0110_g_l2";
			qcom,set = <RPMH_REGULATOR_SET_ALL>;
			regulator-min-microvolt = <1800000>;
			regulator-max-microvolt = <1800000>;
			qcom,init-voltage = <1800000>;
			qcom,init-mode = <RPMH_REGULATOR_MODE_AUTO>;
		};
	};

	rpmh-regulator-l3g-e0 {
		compatible = "qcom,rpmh-vrm-regulator";
		qcom,resource-name = "L3G_E0";
		qcom,regulator-type = "pmic7-ldo";
		qcom,supported-modes = <RPMH_REGULATOR_MODE_LPM
					RPMH_REGULATOR_MODE_AUTO>;
		qcom,mode-threshold-currents = <0 30000>;

		L3G: L3G_E0: pmh0110_g_l3: regulator-pmh0110-g-l3 {
			regulator-name = "pmh0110_g_l3";
			qcom,set = <RPMH_REGULATOR_SET_ALL>;
			regulator-min-microvolt = <1200000>;
			regulator-max-microvolt = <1200000>;
			qcom,init-voltage = <1200000>;
			qcom,init-mode = <RPMH_REGULATOR_MODE_AUTO>;
		};
	};

	rpmh-regulator-l4g-e0 {
		compatible = "qcom,rpmh-vrm-regulator";
		qcom,resource-name = "L4G_E0";
		qcom,regulator-type = "pmic7-ldo";
		qcom,supported-modes = <RPMH_REGULATOR_MODE_LPM
					RPMH_REGULATOR_MODE_AUTO>;
		qcom,mode-threshold-currents = <0 30000>;

		L4G: L4G_E0: pmh0110_g_l4: regulator-pmh0110-g-l4 {
			regulator-name = "pmh0110_g_l4";
			qcom,set = <RPMH_REGULATOR_SET_ALL>;
			regulator-min-microvolt = <912000>;
			regulator-max-microvolt = <912000>;
			qcom,init-voltage = <912000>;
			qcom,init-mode = <RPMH_REGULATOR_MODE_AUTO>;
		};
	};

	rpmh-regulator-s7i-e0 {
		compatible = "qcom,rpmh-vrm-regulator";
		qcom,resource-name = "S7I_E0";

		S7I: S7I_E0: pmh0110_i_s7: regulator-pmh0110-i-s7 {
			regulator-name = "pmh0110_i_s7";
			qcom,set = <RPMH_REGULATOR_SET_ALL>;
			regulator-min-microvolt = <900000>;
			regulator-max-microvolt = <972000>;
			qcom,init-voltage = <904000>;
		};
	};

	rpmh-regulator-l2i-e0 {
		compatible = "qcom,rpmh-vrm-regulator";
		qcom,resource-name = "L2I_E0";
		qcom,regulator-type = "pmic7-ldo";
		qcom,supported-modes = <RPMH_REGULATOR_MODE_RET
					RPMH_REGULATOR_MODE_AUTO>;
		qcom,mode-threshold-currents = <0 30000>;

		L2I: L2I_E0: pmh0110_i_l2: regulator-pmh0110-i-l2 {
			regulator-name = "pmh0110_i_l2";
			qcom,set = <RPMH_REGULATOR_SET_ALL>;
			regulator-min-microvolt = <1200000>;
			regulator-max-microvolt = <1200000>;
			qcom,init-voltage = <1200000>;
			qcom,init-mode = <RPMH_REGULATOR_MODE_AUTO>;
		};
	};

	rpmh-regulator-l3i-e0 {
		compatible = "qcom,rpmh-vrm-regulator";
		qcom,resource-name = "L3I_E0";
		qcom,regulator-type = "pmic7-ldo";
		qcom,supported-modes = <RPMH_REGULATOR_MODE_LPM
					RPMH_REGULATOR_MODE_AUTO>;
		qcom,mode-threshold-currents = <0 30000>;

		L3I: L3I_E0: pmh0110_i_l3: regulator-pmh0110-i-l3 {
			regulator-name = "pmh0110_i_l3";
			qcom,set = <RPMH_REGULATOR_SET_ALL>;
			regulator-min-microvolt = <880000>;
			regulator-max-microvolt = <920000>;
			qcom,init-voltage = <880000>;
			qcom,init-mode = <RPMH_REGULATOR_MODE_AUTO>;
		};
	};

	rpmh-regulator-l4i-e0 {
		compatible = "qcom,rpmh-vrm-regulator";
		qcom,resource-name = "L4I_E0";
		qcom,regulator-type = "pmic7-ldo";
		qcom,supported-modes = <RPMH_REGULATOR_MODE_LPM
					RPMH_REGULATOR_MODE_AUTO>;
		qcom,mode-threshold-currents = <0 30000>;

		L4I: L4I_E0: pmh0110_i_l4: regulator-pmh0110-i-l4 {
			regulator-name = "pmh0110_i_l4";
			qcom,set = <RPMH_REGULATOR_SET_ALL>;
			regulator-min-microvolt = <1800000>;
			regulator-max-microvolt = <1800000>;
			qcom,init-voltage = <1800000>;
			qcom,init-mode = <RPMH_REGULATOR_MODE_AUTO>;
		};
	};

	rpmh-regulator-s1j-e1 {
		compatible = "qcom,rpmh-vrm-regulator";
		qcom,resource-name = "S1J_E1";

		S1J: S1J_E1: pmh0104_s1: regulator-pmh0104-s1 {
			regulator-name = "pmh0104_s1";
			qcom,set = <RPMH_REGULATOR_SET_ALL>;
			regulator-min-microvolt = <400000>;
			regulator-max-microvolt = <1000000>;
			qcom,init-voltage = <852000>;
		};
	};

	rpmh-regulator-s2j-e1 {
		compatible = "qcom,rpmh-vrm-regulator";
		qcom,resource-name = "S2J_E1";

		S2J: S2J_E1: pmh0104_s2: regulator-pmh0104-s2 {
			regulator-name = "pmh0104_s2";
			qcom,set = <RPMH_REGULATOR_SET_ALL>;
			regulator-min-microvolt = <500000>;
			regulator-max-microvolt = <1100000>;
			qcom,init-voltage = <852000>;
		};
	};

	rpmh-regulator-s3j-e1 {
		compatible = "qcom,rpmh-vrm-regulator";
		qcom,resource-name = "S3J_E1";

		S3J: S3J_E1: pmh0104_s3: regulator-pmh0104-s3 {
			regulator-name = "pmh0104_s3";
			qcom,set = <RPMH_REGULATOR_SET_ALL>;
			regulator-min-microvolt = <1200000>;
			regulator-max-microvolt = <1300000>;
			qcom,init-voltage = <1224000>;
		};
	};

	rpmh-regulator-s4j-e1 {
		compatible = "qcom,rpmh-vrm-regulator";
		qcom,resource-name = "S4J_E1";

		S4J: S4J_E1: pmh0104_s4: regulator-pmh0104-s4 {
			regulator-name = "pmh0104_s4";
			qcom,set = <RPMH_REGULATOR_SET_ALL>;
			regulator-min-microvolt = <300000>;
			regulator-max-microvolt = <1000000>;
			qcom,init-voltage = <752000>;
		};
	};

	rpmh-regulator-l1k-e1 {
		compatible = "qcom,rpmh-vrm-regulator";
		qcom,resource-name = "L1K_E1";
		qcom,regulator-type = "pmic5-ldo";
		qcom,supported-modes = <RPMH_REGULATOR_MODE_LPM
					RPMH_REGULATOR_MODE_HPM>;
		qcom,mode-threshold-currents = <0 30000>;

		L1K: L1K_E1: pmr735d_l1: regulator-pmr735d-l1 {
			regulator-name = "pmr735d_l1";
			qcom,set = <RPMH_REGULATOR_SET_ALL>;
			regulator-min-microvolt = <300000>;
			regulator-max-microvolt = <1100000>;
			qcom,init-voltage = <856000>;
			qcom,init-mode = <RPMH_REGULATOR_MODE_HPM>;
		};
	};

	rpmh-regulator-l2k-e1 {
		compatible = "qcom,rpmh-vrm-regulator";
		qcom,resource-name = "L2K_E1";
		qcom,regulator-type = "pmic5-ldo";
		qcom,supported-modes = <RPMH_REGULATOR_MODE_LPM
					RPMH_REGULATOR_MODE_HPM>;
		qcom,mode-threshold-currents = <0 30000>;

		L2K: L2K_E1: pmr735d_l2: regulator-pmr735d-l2 {
			regulator-name = "pmr735d_l2";
			qcom,set = <RPMH_REGULATOR_SET_ALL>;
			regulator-min-microvolt = <700000>;
			regulator-max-microvolt = <1000000>;
			qcom,init-voltage = <700000>;
			qcom,init-mode = <RPMH_REGULATOR_MODE_HPM>;
		};
	};

	rpmh-regulator-l3k-e1 {
		compatible = "qcom,rpmh-vrm-regulator";
		qcom,resource-name = "L3K_E1";
		qcom,regulator-type = "pmic5-ldo";
		qcom,supported-modes = <RPMH_REGULATOR_MODE_PASS
					RPMH_REGULATOR_MODE_HPM>;
		qcom,mode-threshold-currents = <0 25>;

		L3K: L3K_E1: pmr735d_l3: regulator-pmr735d-l3 {
			regulator-name = "pmr735d_l3";
			qcom,set = <RPMH_REGULATOR_SET_ALL>;
			regulator-min-microvolt = <1200000>;
			regulator-max-microvolt = <1200000>;
			qcom,init-voltage = <1200000>;
			qcom,init-mode = <RPMH_REGULATOR_MODE_HPM>;
		};
	};

	rpmh-regulator-l4k-e1 {
		compatible = "qcom,rpmh-vrm-regulator";
		qcom,resource-name = "L4K_E1";
		qcom,regulator-type = "pmic5-ldo";
		qcom,supported-modes = <RPMH_REGULATOR_MODE_LPM
					RPMH_REGULATOR_MODE_HPM>;
		qcom,mode-threshold-currents = <0 30000>;

		L4K: L4K_E1: pmr735d_l4: regulator-pmr735d-l4 {
			regulator-name = "pmr735d_l4";
			qcom,set = <RPMH_REGULATOR_SET_ALL>;
			regulator-min-microvolt = <1000000>;
			regulator-max-microvolt = <1200000>;
			qcom,init-voltage = <1000000>;
			qcom,init-mode = <RPMH_REGULATOR_MODE_HPM>;
		};
	};

	rpmh-regulator-l5k-e1 {
		compatible = "qcom,rpmh-vrm-regulator";
		qcom,resource-name = "L5K_E1";
		qcom,regulator-type = "pmic5-ldo";
		qcom,supported-modes = <RPMH_REGULATOR_MODE_LPM
					RPMH_REGULATOR_MODE_HPM>;
		qcom,mode-threshold-currents = <0 30000>;

		L5K: L5K_E1: pmr735d_l5: regulator-pmr735d-l5 {
			regulator-name = "pmr735d_l5";
			qcom,set = <RPMH_REGULATOR_SET_ALL>;
			regulator-min-microvolt = <700000>;
			regulator-max-microvolt = <1000000>;
			qcom,init-voltage = <700000>;
			qcom,init-mode = <RPMH_REGULATOR_MODE_HPM>;
		};
	};

	rpmh-regulator-l6k-e1 {
		compatible = "qcom,rpmh-vrm-regulator";
		qcom,resource-name = "L6K_E1";
		qcom,regulator-type = "pmic5-ldo";
		qcom,supported-modes = <RPMH_REGULATOR_MODE_LPM
					RPMH_REGULATOR_MODE_HPM>;
		qcom,mode-threshold-currents = <0 30000>;

		L6K: L6K_E1: pmr735d_l6: regulator-pmr735d-l6 {
			regulator-name = "pmr735d_l6";
			qcom,set = <RPMH_REGULATOR_SET_ALL>;
			regulator-min-microvolt = <1700000>;
			regulator-max-microvolt = <2000000>;
			qcom,init-voltage = <1700000>;
			qcom,init-mode = <RPMH_REGULATOR_MODE_HPM>;
		};
	};

	rpmh-regulator-l7k-e1 {
		compatible = "qcom,rpmh-vrm-regulator";
		qcom,resource-name = "L7K_E1";
		qcom,regulator-type = "pmic5-ldo";
		qcom,supported-modes = <RPMH_REGULATOR_MODE_LPM
					RPMH_REGULATOR_MODE_HPM>;
		qcom,mode-threshold-currents = <0 30000>;

		L7K: L7K_E1: pmr735d_l7: regulator-pmr735d-l7 {
			regulator-name = "pmr735d_l7";
			qcom,set = <RPMH_REGULATOR_SET_ALL>;
			regulator-min-microvolt = <700000>;
			regulator-max-microvolt = <848000>;
			qcom,init-voltage = <700000>;
			qcom,init-mode = <RPMH_REGULATOR_MODE_HPM>;
		};
	};

	rpmh-regulator-l1m-e1 {
		compatible = "qcom,rpmh-vrm-regulator";
		qcom,resource-name = "L1M_E1";
		qcom,regulator-type = "pmic5-ldo";
		qcom,supported-modes = <RPMH_REGULATOR_MODE_LPM
					RPMH_REGULATOR_MODE_HPM>;
		qcom,mode-threshold-currents = <0 100000>;

		L1M: L1M_E1: pm8010_m_l1: regulator-pm8010-m-l1 {
			regulator-name = "pm8010_m_l1";
			qcom,set = <RPMH_REGULATOR_SET_ALL>;
			regulator-min-microvolt = <1000000>;
			regulator-max-microvolt = <1100000>;
			qcom,init-voltage = <1000000>;
			qcom,init-mode = <RPMH_REGULATOR_MODE_HPM>;
		};
	};

	rpmh-regulator-l2m-e1 {
		compatible = "qcom,rpmh-vrm-regulator";
		qcom,resource-name = "L2M_E1";
		qcom,regulator-type = "pmic5-ldo";
		qcom,supported-modes = <RPMH_REGULATOR_MODE_LPM
					RPMH_REGULATOR_MODE_HPM>;
		qcom,mode-threshold-currents = <0 100000>;

		L2M: L2M_E1: pm8010_m_l2: regulator-pm8010-m-l2 {
			regulator-name = "pm8010_m_l2";
			qcom,set = <RPMH_REGULATOR_SET_ALL>;
			regulator-min-microvolt = <1096000>;
			regulator-max-microvolt = <1104000>;
			qcom,init-voltage = <1096000>;
			qcom,init-mode = <RPMH_REGULATOR_MODE_HPM>;
		};
	};

	rpmh-regulator-l3m-e1 {
		compatible = "qcom,rpmh-vrm-regulator";
		qcom,resource-name = "L3M_E1";

		L3M: L3M_E1: pm8010_m_l3: regulator-pm8010-m-l3 {
			regulator-name = "pm8010_m_l3";
			qcom,set = <RPMH_REGULATOR_SET_ALL>;
			regulator-min-microvolt = <2800000>;
			regulator-max-microvolt = <2900000>;
			qcom,init-voltage = <2800000>;
		};
	};

	rpmh-regulator-l4m-e1 {
		compatible = "qcom,rpmh-vrm-regulator";
		qcom,resource-name = "L4M_E1";

		L4M: L4M_E1: pm8010_m_l4: regulator-pm8010-m-l4 {
			regulator-name = "pm8010_m_l4";
			qcom,set = <RPMH_REGULATOR_SET_ALL>;
			regulator-min-microvolt = <2200000>;
			regulator-max-microvolt = <2200000>;
			qcom,init-voltage = <2200000>;
		};
	};

	rpmh-regulator-l5m-e1 {
		compatible = "qcom,rpmh-vrm-regulator";
		qcom,resource-name = "L5M_E1";

		L5M: L5M_E1: pm8010_m_l5: regulator-pm8010-m-l5 {
			regulator-name = "pm8010_m_l5";
			qcom,set = <RPMH_REGULATOR_SET_ALL>;
			regulator-min-microvolt = <1200000>;
			regulator-max-microvolt = <1800000>;
			qcom,init-voltage = <1800000>;
		};
	};

	rpmh-regulator-l6m-e1 {
		compatible = "qcom,rpmh-vrm-regulator";
		qcom,resource-name = "L6M_E1";

		L6M: L6M_E1: pm8010_m_l6: regulator-pm8010-m-l6 {
			regulator-name = "pm8010_m_l6";
			qcom,set = <RPMH_REGULATOR_SET_ALL>;
			regulator-min-microvolt = <2800000>;
			regulator-max-microvolt = <2800000>;
			qcom,init-voltage = <2800000>;
		};
	};

	rpmh-regulator-l7m-e1 {
		compatible = "qcom,rpmh-vrm-regulator";
		qcom,resource-name = "L7M_E1";

		L7M: L7M_E1: pm8010_m_l7: regulator-pm8010-m-l7 {
			regulator-name = "pm8010_m_l7";
			qcom,set = <RPMH_REGULATOR_SET_ALL>;
			regulator-min-microvolt = <2800000>;
			regulator-max-microvolt = <2800000>;
			qcom,init-voltage = <2800000>;
		};
	};

	rpmh-regulator-l1n-e1 {
		compatible = "qcom,rpmh-vrm-regulator";
		qcom,resource-name = "L1N_E1";
		qcom,regulator-type = "pmic5-ldo";
		qcom,supported-modes = <RPMH_REGULATOR_MODE_LPM
					RPMH_REGULATOR_MODE_HPM>;
		qcom,mode-threshold-currents = <0 100000>;

		L1N: L1N_E1: pm8010_n_l1: regulator-pm8010-n-l1 {
			regulator-name = "pm8010_n_l1";
			qcom,set = <RPMH_REGULATOR_SET_ALL>;
			regulator-min-microvolt = <1096000>;
			regulator-max-microvolt = <1200000>;
			qcom,init-voltage = <1096000>;
			qcom,init-mode = <RPMH_REGULATOR_MODE_HPM>;
		};
	};

	rpmh-regulator-l2n-e1 {
		compatible = "qcom,rpmh-vrm-regulator";
		qcom,resource-name = "L2N_E1";
		qcom,regulator-type = "pmic5-ldo";
		qcom,supported-modes = <RPMH_REGULATOR_MODE_LPM
					RPMH_REGULATOR_MODE_HPM>;
		qcom,mode-threshold-currents = <0 100000>;

		L2N: L2N_E1: pm8010_n_l2: regulator-pm8010-n-l2 {
			regulator-name = "pm8010_n_l2";
			qcom,set = <RPMH_REGULATOR_SET_ALL>;
			regulator-min-microvolt = <1200000>;
			regulator-max-microvolt = <1200000>;
			qcom,init-voltage = <1200000>;
			qcom,init-mode = <RPMH_REGULATOR_MODE_HPM>;
		};
	};

	rpmh-regulator-l3n-e1 {
		compatible = "qcom,rpmh-vrm-regulator";
		qcom,resource-name = "L3N_E1";

		L3N: L3N_E1: pm8010_n_l3: regulator-pm8010-n-l3 {
			regulator-name = "pm8010_n_l3";
			qcom,set = <RPMH_REGULATOR_SET_ALL>;
			regulator-min-microvolt = <1800000>;
			regulator-max-microvolt = <1800000>;
			qcom,init-voltage = <1800000>;
		};
	};

	rpmh-regulator-l4n-e1 {
		compatible = "qcom,rpmh-vrm-regulator";
		qcom,resource-name = "L4N_E1";

		L4N: L4N_E1: pm8010_n_l4: regulator-pm8010-n-l4 {
			regulator-name = "pm8010_n_l4";
			qcom,set = <RPMH_REGULATOR_SET_ALL>;
			regulator-min-microvolt = <1800000>;
			regulator-max-microvolt = <1800000>;
			qcom,init-voltage = <1800000>;
		};
	};

	rpmh-regulator-l5n-e1 {
		compatible = "qcom,rpmh-vrm-regulator";
		qcom,resource-name = "L5N_E1";

		L5N: L5N_E1: pm8010_n_l5: regulator-pm8010-n-l5 {
			regulator-name = "pm8010_n_l5";
			qcom,set = <RPMH_REGULATOR_SET_ALL>;
			regulator-min-microvolt = <2800000>;
			regulator-max-microvolt = <2800000>;
			qcom,init-voltage = <2800000>;
		};
	};

	rpmh-regulator-l6n-e1 {
		compatible = "qcom,rpmh-vrm-regulator";
		qcom,resource-name = "L6N_E1";

		L6N: L6N_E1: pm8010_n_l6: regulator-pm8010-n-l6 {
			regulator-name = "pm8010_n_l6";
			qcom,set = <RPMH_REGULATOR_SET_ALL>;
			regulator-min-microvolt = <2800000>;
			regulator-max-microvolt = <2800000>;
			qcom,init-voltage = <2800000>;
		};
	};

	rpmh-regulator-l7n-e1 {
		compatible = "qcom,rpmh-vrm-regulator";
		qcom,resource-name = "L7N_E1";

		L7N: L7N_E1: pm8010_n_l7: regulator-pm8010-n-l7 {
			regulator-name = "pm8010_n_l7";
			qcom,set = <RPMH_REGULATOR_SET_ALL>;
			regulator-min-microvolt = <3304000>;
			regulator-max-microvolt = <3304000>;
			qcom,init-voltage = <3304000>;
		};
	};

	rpmh-regulator-vrm-wcal {
		compatible = "qcom,rpmh-pbs-regulator";
		qcom,resource-name = "vrm.wcal";

		WCAL_PBS:
		pmk8850_wcal_pbs: regulator-pmk8850-wcal-pbs {
			regulator-name = "pmk8850_wcal_pbs";
			qcom,set = <RPMH_REGULATOR_SET_ALL>;
		};
	};
};
